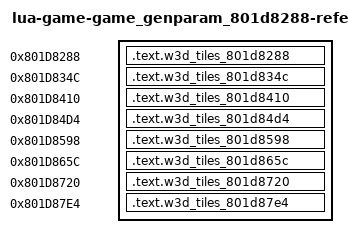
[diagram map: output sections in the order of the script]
/* Generated reference-only placements. All bodies are source-built. */
OUTPUT_FORMAT("elf32-powerpc")
OUTPUT_ARCH(powerpc)
ENTRY(w3d_tiles_801d8288)
_SDA_BASE_ = 0x804b2540;
_SDA2_BASE_ = 0x804c2540;
fn_801d7914 = 0x801d7914;
fn_801d79f0 = 0x801d79f0;
fn_801d7ad0 = 0x801d7ad0;
fn_801d7bb4 = 0x801d7bb4;
fn_801d7c94 = 0x801d7c94;
fn_801d7e20 = 0x801d7e20;
fn_801d8034 = 0x801d8034;
fn_801d814c = 0x801d814c;
SECTIONS {
  .text.w3d_tiles_801d8288 0x801d8288 : { *(.text.w3d_tiles_801d8288) }
  .text.w3d_tiles_801d834c 0x801d834c : { *(.text.w3d_tiles_801d834c) }
  .text.w3d_tiles_801d8410 0x801d8410 : { *(.text.w3d_tiles_801d8410) }
  .text.w3d_tiles_801d84d4 0x801d84d4 : { *(.text.w3d_tiles_801d84d4) }
  .text.w3d_tiles_801d8598 0x801d8598 : { *(.text.w3d_tiles_801d8598) }
  .text.w3d_tiles_801d865c 0x801d865c : { *(.text.w3d_tiles_801d865c) }
  .text.w3d_tiles_801d8720 0x801d8720 : { *(.text.w3d_tiles_801d8720) }
  .text.w3d_tiles_801d87e4 0x801d87e4 : { *(.text.w3d_tiles_801d87e4) }
  /DISCARD/ : { *(.text*) *(.rodata*) *(.data*) *(.bss*) *(.sdata*) *(.sbss*) *(.comment) }
}
